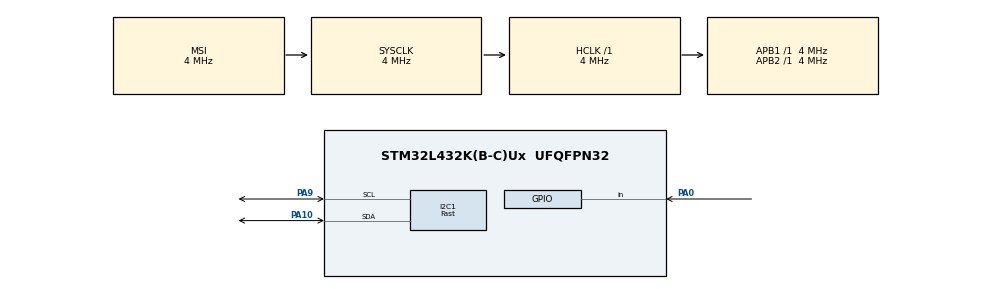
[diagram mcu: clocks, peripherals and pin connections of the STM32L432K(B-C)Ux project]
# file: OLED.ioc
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I2C1.I2C_Speed_Mode=I2C_Fast
I2C1.Timing=0x00000004
Mcu.Family=STM32L4
Mcu.Name=STM32L432K(B-C)Ux
Mcu.Package=UFQFPN32
NVIC.PriorityGroup=NVIC_PRIORITYGROUP_4
PA0.Signal=GPIO_Input
PA10.Mode=I2C
PA10.Signal=I2C1_SDA
PA13\ (JTMS-SWDIO).Mode=Serial_Wire
PA13\ (JTMS-SWDIO).Signal=SYS_JTMS-SWDIO
PA14\ (JTCK-SWCLK).Mode=Serial_Wire
PA14\ (JTCK-SWCLK).Signal=SYS_JTCK-SWCLK
PA9.Mode=I2C
PA9.Signal=I2C1_SCL
PC14-OSC32_IN\ (PC14).Mode=LSE-External-Oscillator
PC14-OSC32_IN\ (PC14).Signal=RCC_OSC32_IN
PC15-OSC32_OUT\ (PC15).Mode=LSE-External-Oscillator
PC15-OSC32_OUT\ (PC15).Signal=RCC_OSC32_OUT
ProjectManager.HeapSize=0x200
ProjectManager.StackSize=0x400
ProjectManager.TargetToolchain=MDK-ARM V5
RCC.ADCFreq_Value=16000000
RCC.AHBFreq_Value=4000000
RCC.APB1Freq_Value=4000000
RCC.APB1TimFreq_Value=4000000
RCC.APB2Freq_Value=4000000
RCC.APB2TimFreq_Value=4000000
RCC.CortexFreq_Value=4000000
RCC.HCLKFreq_Value=4000000
RCC.HSE_VALUE=8000000
RCC.HSI48_VALUE=48000000
RCC.HSI_VALUE=16000000
RCC.MSI_VALUE=4000000
RCC.PLLN=40
RCC.SYSCLKFreq_VALUE=4000000
RCC.USBFreq_Value=16000000
RCC.VCOOutputFreq_Value=160000000
board=custom

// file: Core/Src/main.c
/* USER CODE BEGIN Header */
/**
  ******************************************************************************
  * @file           : main.c
  * @brief          : Main program body
  ******************************************************************************
  * @attention
  *
  * <h2><center>&copy; Copyright (c) 2021 STMicroelectronics.
  * All rights reserved.</center></h2>
  *
  * This software component is licensed by ST under BSD 3-Clause license,
  * the "License"; You may not use this file except in compliance with the
  * License. You may obtain a copy of the License at:
  *                        opensource.org/licenses/BSD-3-Clause
  *
  ******************************************************************************
  */
/* USER CODE END Header */
#include "main.h"

/* USER CODE BEGIN Includes */
#include "ssd1306.h"
#include "fonts.h"
/* USER CODE END Includes */

I2C_HandleTypeDef hi2c1;

void SystemClock_Config(void);
static void MX_GPIO_Init(void);
static void MX_I2C1_Init(void);

/* USER CODE BEGIN 0 */
uint8_t check;
/* USER CODE END 0 */

int main(void)
{

  /* MCU Configuration--------------------------------------------------------*/

  /* Reset of all peripherals, Initializes the Flash interface and the Systick. */
  HAL_Init();

  /* Configure the system clock */
  SystemClock_Config();

  /* Initialize all configured peripherals */
  MX_GPIO_Init();
  MX_I2C1_Init();
  /* USER CODE BEGIN 2 */
	SSD1306_Init();

	SSD1306_Clear ();
	//check = SSD1306_Init ();
	SSD1306_Fill (0); 												//fill color 0 ie black
	SSD1306_UpdateScreen();										//print the changes on the display

	SSD1306_GotoXY (0,0); 										//Goto 0,0
	SSD1306_Puts("HELLO", &Font_11x18, 0x01);		//puts HELLO on the display with color ie blue
	SSD1306_UpdateScreen();										//print the changes on the display
//
//	SSD1306_GotoXY (10,0); 										//Goto 10,10
//	SSD1306_Puts("WORLD", &Font_11x18, 1);		//puts WORLD on the display
//
//	SSD1306_UpdateScreen();										//print the changes on the display
//
//	HAL_Delay (1000);
//	//Clear the screen
//	SSD1306_Fill(0); 												//fill color 0 ie black
//	SSD1306_UpdateScreen();										//print the changes on the display
//	SSD1306_DrawCircle (20,10,5,1);						//Draw circle
//	SSD1306_UpdateScreen();										//print the changes on the display
//
//	SSD1306_DrawFilledRectangle(60,40,20,30,1);
//	SSD1306_UpdateScreen();										//print the changes on the display

  /* USER CODE END 2 */

  /* Infinite loop */
  /* USER CODE BEGIN WHILE */
  while (1)
  {
			SSD1306_Clear ();
//			SSD1306_UpdateScreen();										//print the changes on the display
//			SSD1306_GotoXY (0,0); 										//Goto 0,0
//			SSD1306_Puts("E", &Font_11x18, 1);		//puts WORLD on the display
//			SSD1306_GotoXY (30,0); 										//Goto 10,10
//			SSD1306_Puts("S1", &Font_11x18, 1);		//puts WORLD on the display
//		  SSD1306_GotoXY (60,0); 										//Goto 10,10
//			SSD1306_Puts("S2", &Font_11x18, 1);		//puts WORLD on the display
//  		SSD1306_GotoXY (90,0); 										//Goto 10,10
//			SSD1306_Puts("S3", &Font_11x18, 1);		//puts WORLD on the display
//
//	  	SSD1306_GotoXY (0,20); 										//Goto 0,0
//			SSD1306_Puts("F", &Font_11x18, 1);		//puts WORLD on the display
//	  	SSD1306_GotoXY (30,20); 										//Goto 10,10
//			SSD1306_Puts("S4", &Font_11x18, 1);		//puts WORLD on the display
//		  SSD1306_GotoXY (60,20); 										//Goto 10,10
//			SSD1306_Puts("S5", &Font_11x18, 1);		//puts WORLD on the display
//  		SSD1306_GotoXY (90,20); 										//Goto 10,10
//			SSD1306_Puts("S6", &Font_11x18, 1);		//puts WORLD on the display
//			SSD1306_UpdateScreen();										//print the changes on the display
//

		if (HAL_GPIO_ReadPin(GPIOA, GPIO_PIN_0) == GPIO_PIN_RESET)
		{
			SSD1306_Clear ();
			SSD1306_UpdateScreen();										//print the changes on the display
			SSD1306_GotoXY (0,0); 										//Goto 0,0
			SSD1306_Puts("P1", &Font_11x18, 1);		//puts WORLD on the display
			SSD1306_GotoXY (0,30); 										//Goto 10,10
			SSD1306_Puts("F", &Font_11x18, 1);		//puts WORLD on the display
			SSD1306_UpdateScreen();										//print the changes on the display
		}
		else
		{
			SSD1306_Clear ();
			SSD1306_UpdateScreen();										//print the changes on the display
			SSD1306_GotoXY (0,0); 										//Goto 0,0
			SSD1306_Puts("P1", &Font_11x18, 1);		//puts WORLD on the display
			SSD1306_GotoXY (0,30); 										//Goto 10,10
			SSD1306_Puts("E", &Font_11x18, 1);		//puts WORLD on the display
			SSD1306_UpdateScreen();										//print the changes on the display
		}

		HAL_Delay(500);
    /* USER CODE END WHILE */

  }
}

void SystemClock_Config(void)
{
  RCC_OscInitTypeDef RCC_OscInitStruct = {0};
  RCC_ClkInitTypeDef RCC_ClkInitStruct = {0};
  RCC_PeriphCLKInitTypeDef PeriphClkInit = {0};

  /** Configure LSE Drive Capability
  */
  HAL_PWR_EnableBkUpAccess();
  __HAL_RCC_LSEDRIVE_CONFIG(RCC_LSEDRIVE_LOW);
  /** Initializes the RCC Oscillators according to the specified parameters
  * in the RCC_OscInitTypeDef structure.
  */
  RCC_OscInitStruct.OscillatorType = RCC_OSCILLATORTYPE_LSE|RCC_OSCILLATORTYPE_MSI;
  RCC_OscInitStruct.LSEState = RCC_LSE_ON;
  RCC_OscInitStruct.MSIState = RCC_MSI_ON;
  RCC_OscInitStruct.MSICalibrationValue = 0;
  RCC_OscInitStruct.MSIClockRange = RCC_MSIRANGE_6;
  RCC_OscInitStruct.PLL.PLLState = RCC_PLL_NONE;
  if (HAL_RCC_OscConfig(&RCC_OscInitStruct) != HAL_OK)
  {
    Error_Handler();
  }
  /** Initializes the CPU, AHB and APB buses clocks
  */
  RCC_ClkInitStruct.ClockType = RCC_CLOCKTYPE_HCLK|RCC_CLOCKTYPE_SYSCLK
                              |RCC_CLOCKTYPE_PCLK1|RCC_CLOCKTYPE_PCLK2;
  RCC_ClkInitStruct.SYSCLKSource = RCC_SYSCLKSOURCE_MSI;
  RCC_ClkInitStruct.AHBCLKDivider = RCC_SYSCLK_DIV1;
  RCC_ClkInitStruct.APB1CLKDivider = RCC_HCLK_DIV1;
  RCC_ClkInitStruct.APB2CLKDivider = RCC_HCLK_DIV1;

  if (HAL_RCC_ClockConfig(&RCC_ClkInitStruct, FLASH_LATENCY_0) != HAL_OK)
  {
    Error_Handler();
  }
  PeriphClkInit.PeriphClockSelection = RCC_PERIPHCLK_I2C1;
  PeriphClkInit.I2c1ClockSelection = RCC_I2C1CLKSOURCE_PCLK1;
  if (HAL_RCCEx_PeriphCLKConfig(&PeriphClkInit) != HAL_OK)
  {
    Error_Handler();
  }
  /** Configure the main internal regulator output voltage
  */
  if (HAL_PWREx_ControlVoltageScaling(PWR_REGULATOR_VOLTAGE_SCALE1) != HAL_OK)
  {
    Error_Handler();
  }
  /** Enable MSI Auto calibration
  */
  HAL_RCCEx_EnableMSIPLLMode();
}

static void MX_I2C1_Init(void)
{

  hi2c1.Instance = I2C1;
  hi2c1.Init.Timing = 0x00000004;
  hi2c1.Init.OwnAddress1 = 0;
  hi2c1.Init.AddressingMode = I2C_ADDRESSINGMODE_7BIT;
  hi2c1.Init.DualAddressMode = I2C_DUALADDRESS_DISABLE;
  hi2c1.Init.OwnAddress2 = 0;
  hi2c1.Init.OwnAddress2Masks = I2C_OA2_NOMASK;
  hi2c1.Init.GeneralCallMode = I2C_GENERALCALL_DISABLE;
  hi2c1.Init.NoStretchMode = I2C_NOSTRETCH_DISABLE;
  if (HAL_I2C_Init(&hi2c1) != HAL_OK)
  {
    Error_Handler();
  }
  /** Configure Analogue filter
  */
  if (HAL_I2CEx_ConfigAnalogFilter(&hi2c1, I2C_ANALOGFILTER_ENABLE) != HAL_OK)
  {
    Error_Handler();
  }
  /** Configure Digital filter
  */
  if (HAL_I2CEx_ConfigDigitalFilter(&hi2c1, 0) != HAL_OK)
  {
    Error_Handler();
  }

}

static void MX_GPIO_Init(void)
{
  GPIO_InitTypeDef GPIO_InitStruct = {0};

  /* GPIO Ports Clock Enable */
  __HAL_RCC_GPIOC_CLK_ENABLE();
  __HAL_RCC_GPIOA_CLK_ENABLE();

  /*Configure GPIO pin : PA0 */
  GPIO_InitStruct.Pin = GPIO_PIN_0;
  GPIO_InitStruct.Mode = GPIO_MODE_INPUT;
  GPIO_InitStruct.Pull = GPIO_NOPULL;
  HAL_GPIO_Init(GPIOA, &GPIO_InitStruct);

}

void Error_Handler(void)
{
  __disable_irq();
  while (1)
  {
  }
}

/************************ (C) COPYRIGHT STMicroelectronics *****END OF FILE****/
